# STM32N647 register map
File version: 1.0
CPU: CM55 r0p1, little endian, no MPU, FPU, vendor SysTick, 8 interrupt priority bits
Registers are 32-bit, read-write, reset 0x0 unless marked. A register's access mark holds for its fields unless they carry their own. Offsets are from the block's base; [hi:lo] are bit positions; {n}, {i} and the like mark numbered series; 'fields as' and 'values as' point back to an identical list.

## RCC (part 1 of 2) — Reset and clock control
Base 0x46028000
Same registers: RCC_S 0x56028000
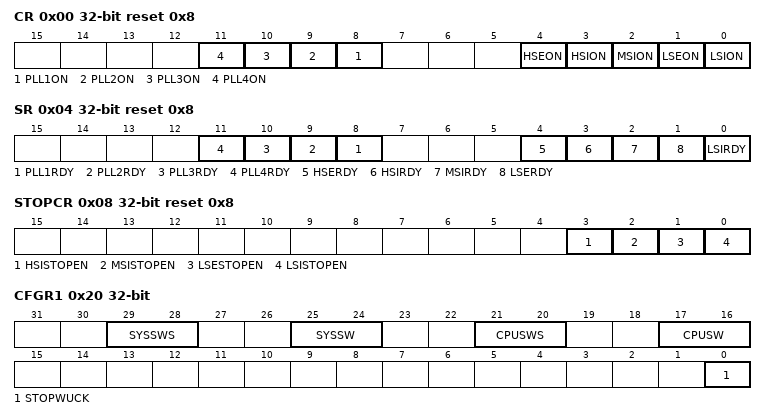
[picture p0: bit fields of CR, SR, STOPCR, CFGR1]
0x00 CR reset 0x8 — RCC control register
  [n+7] PLL{n}ON (n=1..4) — PLL{n} enable in Run/Sleep mode.
  [4] HSEON — HSE oscillator enable in Run/Sleep mode.
  [3] HSION — HSI oscillator enable in Run/Sleep mode.
  [2] MSION — MSI oscillator enable in Run/Sleep mode.
  [1] LSEON — LSE oscillator enable in Run/Sleep mode.
  [0] LSION — LSI oscillator enable in Run/Sleep mode.
0x04 SR ro reset 0x8 — RCC status register
  [n+7] PLL{n}RDY (n=1..4) — PLL{n} clock ready flag
  [4] HSERDY — HSE clock ready flag
  [3] HSIRDY — HSI clock ready flag
  [2] MSIRDY — MSI clock ready flag
  [1] LSERDY — LSE clock ready flag
  [0] LSIRDY — LSI clock ready flag
0x08 STOPCR reset 0x8 — RCC Stop mode control register
  [3] HSISTOPEN — HSI oscillator enable in Stop mode.
  [2] MSISTOPEN — MSI oscillator enable in Stop mode.
  [1] LSESTOPEN — LSE oscillator enable in Stop mode.
  [0] LSISTOPEN — LSI oscillator enable in Stop mode.
0x20 CFGR1 access per field — RCC configuration register 1
  [29:28] SYSSWS ro — System clock switch status
  [25:24] SYSSW rw — System clock switch selection
  [21:20] CPUSWS ro — CPU clock switch status
  [17:16] CPUSW rw — CPU clock switch selection
  [0] STOPWUCK rw — System clock selection after a wake up from system Stop.
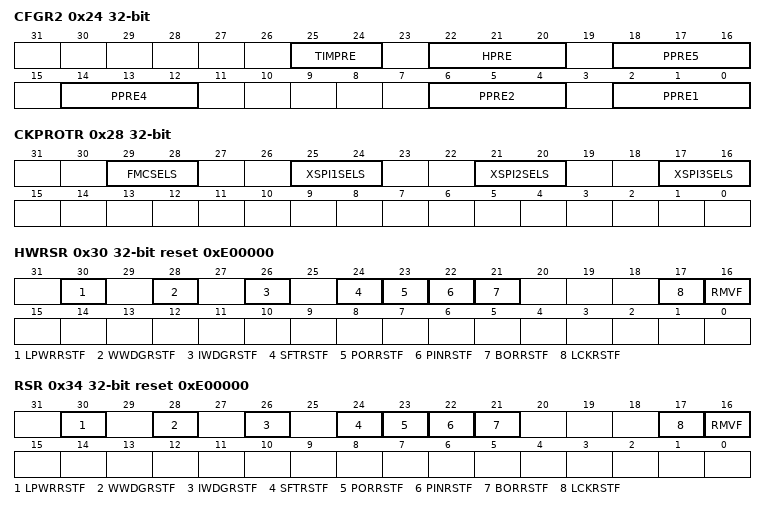
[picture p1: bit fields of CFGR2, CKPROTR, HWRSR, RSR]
0x24 CFGR2 — RCC configuration register 2
  [25:24] TIMPRE — Timers clocks prescaler selection
  [22:20] HPRE — AHB clock prescaler
  [18:16] PPRE5 — CPU domain APB5 prescaler
  [14:12] PPRE4 — CPU domain APB4 prescaler
  [6:4] PPRE2 — CPU domain APB2 prescaler
  [2:0] PPRE1 — CPU domain APB1 prescaler
0x28 CKPROTR ro — RCC clock protection register
  [29:28] FMCSELS — FMC clock selection current status
  [25:24] XSPI1SELS — XSPI1 clock selection current status
  [21:20] XSPI2SELS — XSPI2 clock selection current status
  [17:16] XSPI3SELS — XSPI3 clock selection current status
0x2C BDCR — RCC backup domain protection register
  [31] VSWRST — VSW domain software reset.
0x30 HWRSR access per field reset 0xE00000 — RCC reset status register for hardware
  [30] LPWRRSTF ro — Illegal Stop or Standby flag.
  [28] WWDGRSTF ro — Window watchdog reset flag
  [26] IWDGRSTF ro — Independent Watchdog reset flag.
  [24] SFTRSTF ro — Software system reset flag (1)
  [23] PORRSTF ro — POR/PDR flag.
  [22] PINRSTF ro — Pin reset flag (NRST)
  [21] BORRSTF ro — BOR flag
  [17] LCKRSTF ro — CPU lockup reset flag.
  [16] RMVF wo — Remove reset flag
0x34 RSR access per field reset 0xE00000 — RCC reset register
  [30] LPWRRSTF ro — Illegal Stop or Standby flag.
  [28] WWDGRSTF ro — Window Watchdog reset flag
  [26] IWDGRSTF ro — Independent Watchdog reset flag.
  [24] SFTRSTF ro — Software System reset flag (1)
  [23] PORRSTF ro — POR/PDR flag.
  [22] PINRSTF ro — Pin reset flag (NRST)
  [21] BORRSTF ro — BOR flag
  [17] LCKRSTF ro — CPU lockup reset flag.
  [16] RMVF wo — Remove reset flag
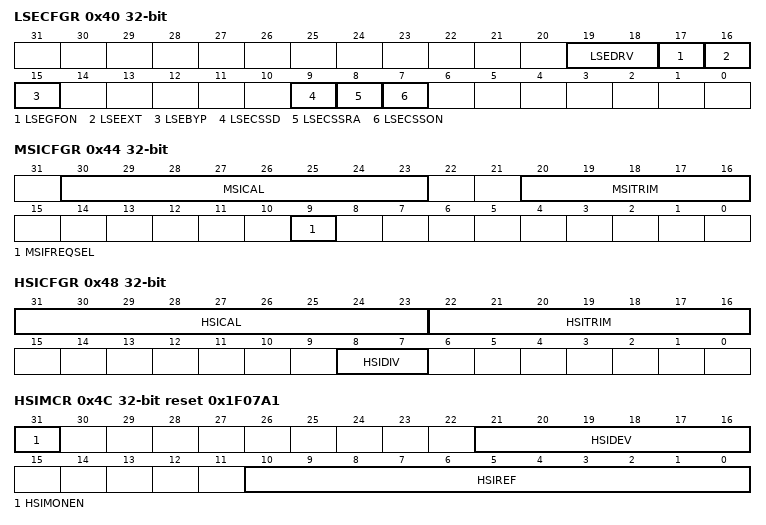
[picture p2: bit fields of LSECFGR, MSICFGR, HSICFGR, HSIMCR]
0x40 LSECFGR access per field — RCC LSE configuration register
  [19:18] LSEDRV rw — LSE oscillator driving capability
  [17] LSEGFON rw — LSE clock glitch filter enable
  [16] LSEEXT rw — LSE clock type in Bypass mode
  [15] LSEBYP rw — LSE clock bypass
  [9] LSECSSD ro — LSE clock security system (CSS) failure detection
  [8] LSECSSRA rw — LSE clock security system (CSS) re-arm function
  [7] LSECSSON wo — LSE clock security system (CSS) enable
0x44 MSICFGR access per field — RCC MSI configuration register
  [30:23] MSICAL ro — MSI clock calibration
  [20:16] MSITRIM rw — MSI clock trimming
  [9] MSIFREQSEL rw — MSI oscillator frequency select
0x48 HSICFGR access per field — RCC HSI configuration register
  [31:23] HSICAL ro — HSI clock calibration
  [22:16] HSITRIM rw — HSI clock trimming
  [8:7] HSIDIV rw — HSI clock divider
0x4C HSIMCR reset 0x1F07A1 — RCC HSI monitor control register
  [31] HSIMONEN — HSI clock period monitor enable
  [21:16] HSIDEV — HSI clock count deviation value
  [10:0] HSIREF — HSI clock cycle counter reference value.
0x50 HSIMSR ro — RCC HSI monitor status register
  [10:0] HSIVAL — HSI clock cycle counter measured value.
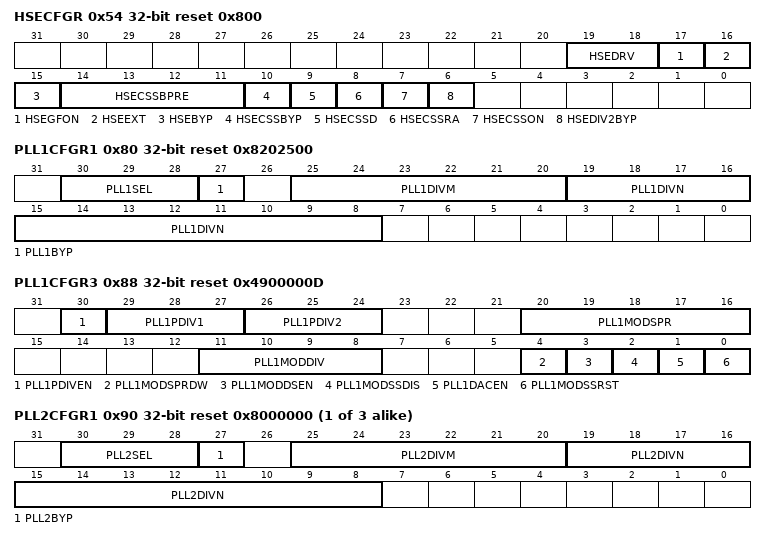
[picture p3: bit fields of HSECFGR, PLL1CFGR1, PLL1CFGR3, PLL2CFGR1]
0x54 HSECFGR access per field reset 0x800 — RCC HSE configuration register
  [19:18] HSEDRV rw — HSE oscillator driving capability
  [17] HSEGFON rw — HSE clock glitch filter enable
  [16] HSEEXT rw — HSE clock type in Bypass mode
  [15] HSEBYP rw — HSE clock bypass
  [14:11] HSECSSBPRE rw — HSE clock security system (CSS) bypass divider
  [10] HSECSSBYP rw — HSE clock security system (CSS) bypass enable
  [9] HSECSSD ro — HSE clock security system (CSS) failure detection
  [8] HSECSSRA rw — HSE clock security system (CSS) re-arm function
  [7] HSECSSON rw — HSE clock security system (CSS) enable
  [6] HSEDIV2BYP rw — HSE div2 oscillator clock in Bypass mode
0x80 PLL1CFGR1 reset 0x8202500 — RCC PLL1 configuration register 1
  [30:28] PLL1SEL — PLL1 source selection of the reference clock
  [27] PLL1BYP — PLL1 bypass
  [25:20] PLL1DIVM — PLL1 reference input clock divide frequency ratio
  [19:8] PLL1DIVN — PLL1 Integer part for the VCO multiplication factor
0x84 PLL1CFGR2 reset 0x800000 — RCC PLL1 configuration register 2
  [23:0] PLL1DIVNFRAC — PLL1 Fractional part of the VCO multiplication factor
0x88 PLL1CFGR3 reset 0x4900000D — RCC PLL1 configuration register 3
  [30] PLL1PDIVEN — PLL1 post divider POSTDIV1, POSTDIV2, and PLL clock output enable
  [29:27] PLL1PDIV1 — PLL1 VCO frequency divider level 1
  [26:24] PLL1PDIV2 — PLL1 VCO frequency divider level 2
  [20:16] PLL1MODSPR — PLL1 Modulation Spread depth adjustment
  [11:8] PLL1MODDIV — PLL1 Modulation Division frequency adjustment
  [4] PLL1MODSPRDW — PLL1 Modulation Spread-Spectrum Down
  [3] PLL1MODDSEN — PLL1 Modulation Spread-Spectrum (and Fractional Divide) enable
  [2] PLL1MODSSDIS — PLL1 Modulation Spread-Spectrum Disable
  [1] PLL1DACEN — PLL1 noise canceling DAC enable in fractional mode.
  [0] PLL1MODSSRST — PLL1 Modulation Spread Spectrum reset
{0x70+0x10*i} PLL{i}CFGR1 reset 0x8000000 (i=2..4) — RCC PLL{i} configuration register 1
  [30:28] PLL{i}SEL — PLL{i} source selection of the reference clock
  [27] PLL{i}BYP — PLL{i} bypass
  [25:20] PLL{i}DIVM — PLL{i} reference input clock divide frequency ratio
  [19:8] PLL{i}DIVN — PLL{i} Integer part for the VCO multiplication factor
{0x74+0x10*i} PLL{i}CFGR2 (i=2..4) — RCC PLL{i} configuration register 2
  [23:0] PLL{i}DIVNFRAC — PLL{i} Fractional part of the VCO multiplication factor
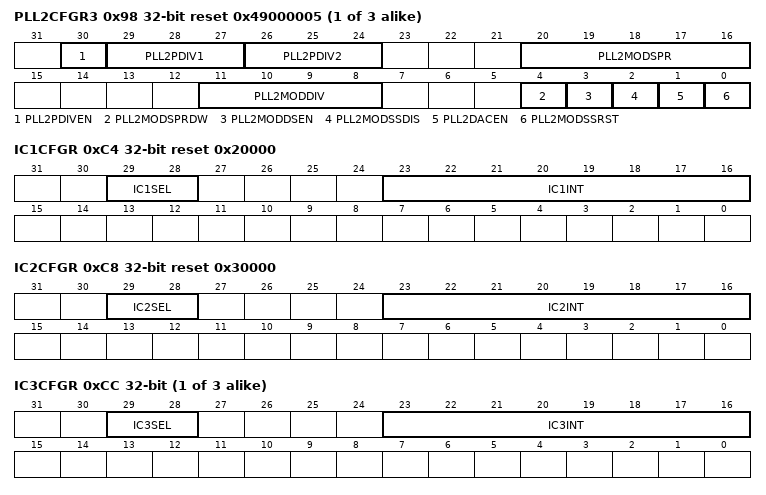
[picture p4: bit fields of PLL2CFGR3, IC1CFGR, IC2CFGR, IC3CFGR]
{0x78+0x10*i} PLL{i}CFGR3 reset 0x49000005 (i=2..4) — RCC PLL{i} configuration register 3
  [30] PLL{i}PDIVEN — PLL{i} post divider POSTDIV1, POSTDIV2, and PLL clock output enable
  [29:27] PLL{i}PDIV1 — PLL{i} VCO frequency divider level 1
  [26:24] PLL{i}PDIV2 — PLL{i} VCO frequency divider level 2
  [20:16] PLL{i}MODSPR — PLL{i} Modulation Spread depth adjustment
  [11:8] PLL{i}MODDIV — PLL{i} Modulation Division frequency adjustment
  [4] PLL{i}MODSPRDW — PLL{i} Modulation Down Spread
  [3] PLL{i}MODDSEN — PLL{i} Modulation Spread-Spectrum (and Fractional Divide) enable
  [2] PLL{i}MODSSDIS — PLL{i} Modulation Spread-Spectrum Disable
  [1] PLL{i}DACEN — PLL{i} noise canceling DAC enable in fractional mode.
  [0] PLL{i}MODSSRST — PLL{i} Modulation Spread Spectrum reset
0xC4 IC1CFGR reset 0x20000 — RCC IC1 configuration register
  [29:28] IC1SEL — Divider IC1 Source Selection
  [23:16] IC1INT — Divider IC1 integer division factor
0xC8 IC2CFGR reset 0x30000 — RCC IC2 configuration register
  [29:28] IC2SEL — Divider IC2 Source Selection
  [23:16] IC2INT — Divider IC2 integer division factor
{0xC0+4i} IC{i}CFGR (i=3..5) — RCC IC{i} configuration register
  [29:28] IC{i}SEL — Divider IC{i} Source Selection
  [23:16] IC{i}INT — Divider IC{i} integer division factor
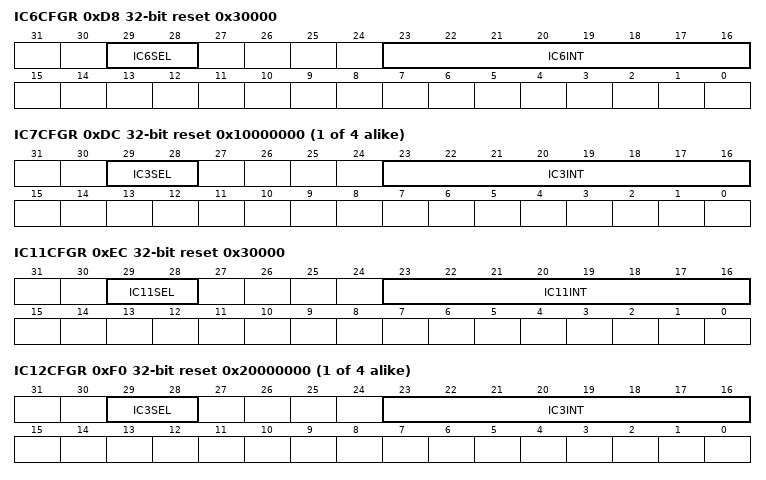
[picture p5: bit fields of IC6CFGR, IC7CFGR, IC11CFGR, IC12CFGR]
0xD8 IC6CFGR reset 0x30000 — RCC IC6 configuration register
  [29:28] IC6SEL — Divider IC6 Source Selection
  [23:16] IC6INT — Divider IC6 integer division factor
{0xC0+4i} IC{i}CFGR reset 0x10000000 (i=7..10) — RCC IC{i} configuration register
  fields as IC3CFGR
0xEC IC11CFGR reset 0x30000 — RCC IC11 configuration register
  [29:28] IC11SEL — Divider IC11 Source Selection
  [23:16] IC11INT — Divider IC11 integer division factor
{0xC0+4i} IC{i}CFGR reset 0x20000000 (i=12..15) — RCC IC{i} configuration register
  fields as IC3CFGR
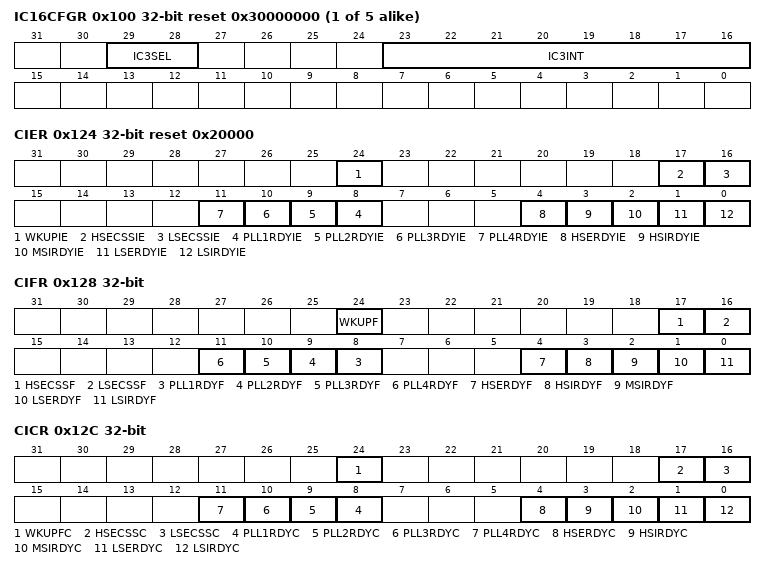
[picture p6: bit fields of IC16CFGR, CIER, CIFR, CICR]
{0xC0+4i} IC{i}CFGR reset 0x30000000 (i=16..20) — RCC IC{i} configuration register
  fields as IC3CFGR
0x124 CIER reset 0x20000 — RCC clock-source interrupt enable register
  [24] WKUPIE — CPU wakeup from Stop interrupt enable
  [17] HSECSSIE — HSE clock security system (CSS) interrupt enable
  [16] LSECSSIE — LSE clock security system (CSS) interrupt enable
  [n+7] PLL{n}RDYIE (n=1..4) — PLL{n} ready interrupt enable
  [4] HSERDYIE — HSE ready interrupt enable
  [3] HSIRDYIE — HSI ready interrupt enable
  [2] MSIRDYIE — MSI ready interrupt enable
  [1] LSERDYIE — LSE ready interrupt enable
  [0] LSIRDYIE — LSI ready interrupt enable
0x128 CIFR ro — RCC clock-source interrupt flag register
  [24] WKUPF — CPU wakeup from Stop interrupt flag
  [17] HSECSSF — HSE ready interrupt flag
  [16] LSECSSF — LSE ready interrupt flag
  [n+7] PLL{n}RDYF (n=1..4) — PLL{n} ready interrupt flag
  [4] HSERDYF — HSE ready interrupt flag
  [3] HSIRDYF — HSI ready interrupt flag
  [2] MSIRDYF — MSI ready interrupt flag
  [1] LSERDYF — LSE ready interrupt flag
  [0] LSIRDYF — LSI ready interrupt flag
0x12C CICR wo — RCC clock-source interrupt Clear register
  [24] WKUPFC — CPU Wakeup ready interrupt clear
  [17] HSECSSC — HSE ready interrupt clear
  [16] LSECSSC — LSE ready interrupt clear
  [n+7] PLL{n}RDYC (n=1..4) — PLL{n} ready interrupt clear
  [4] HSERDYC — HSE ready interrupt clear
  [3] HSIRDYC — HSI ready interrupt clear
  [2] MSIRDYC — MSI ready interrupt clear
  [1] LSERDYC — LSE ready interrupt clear
  [0] LSIRDYC — LSI ready interrupt clear
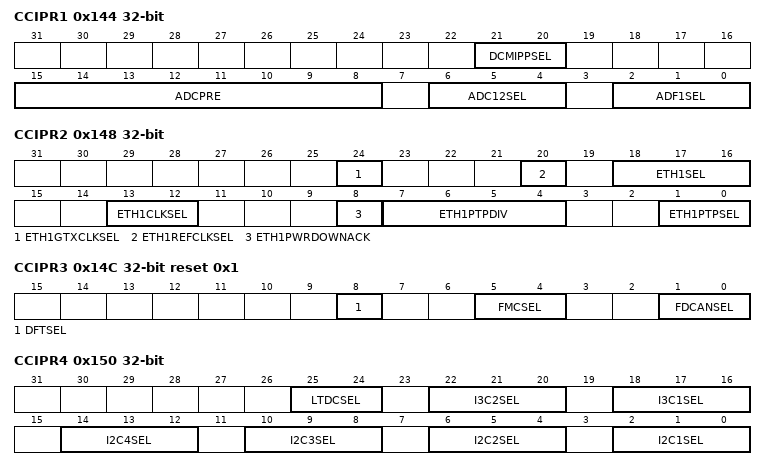
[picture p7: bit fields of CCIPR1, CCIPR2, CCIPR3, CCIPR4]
0x144 CCIPR1 — RCC clock configuration for independent peripheral register1
  [21:20] DCMIPPSEL — Source selection for the DCMIPP kernel clock
  [15:8] ADCPRE — ADC12 Prog clock divider selection (for clock ck_icn_p_adf1)
  [6:4] ADC12SEL — Source selection for the ADC12 kernel clock
  [2:0] ADF1SEL — Source selection for the ADF1 kernel clock
0x148 CCIPR2 access per field — RCC clock configuration for independent peripheral register 2
  [24] ETH1GTXCLKSEL rw — Set and reset by software.
  [20] ETH1REFCLKSEL rw — Set and reset by software
  [18:16] ETH1SEL rw — Set and reset by software
  [13:12] ETH1CLKSEL rw — Source selection for the ETH1 kernel clock
  [8] ETH1PWRDOWNACK ro — Set and reset by software.
  [7:4] ETH1PTPDIV rw — ETH1 Kernel clock divider selection (for clock ck_ker_eth1ptp)
  [1:0] ETH1PTPSEL rw — Source selection for the ETH1 kernel clock
0x14C CCIPR3 reset 0x1 — RCC clock configuration for independent peripheral register3
  [8] DFTSEL — Source selection for the DFT kernel clock
  [5:4] FMCSEL — Source selection for the FMC kernel clock
  [1:0] FDCANSEL — Source selection for the FDCAN kernel clock
0x150 CCIPR4 — RCC clock configuration for independent peripheral register4
  [25:24] LTDCSEL — Source selection for the LTDC kernel clock
  [22:20] I3C2SEL — Source selection for the I3C2 kernel clock
  [18:16] I3C1SEL — Source selection for the I3C1 kernel clock
  [4n-2:4n-4] I2C{n}SEL (n=1..4) — Source selection for the I2C{n} kernel clock
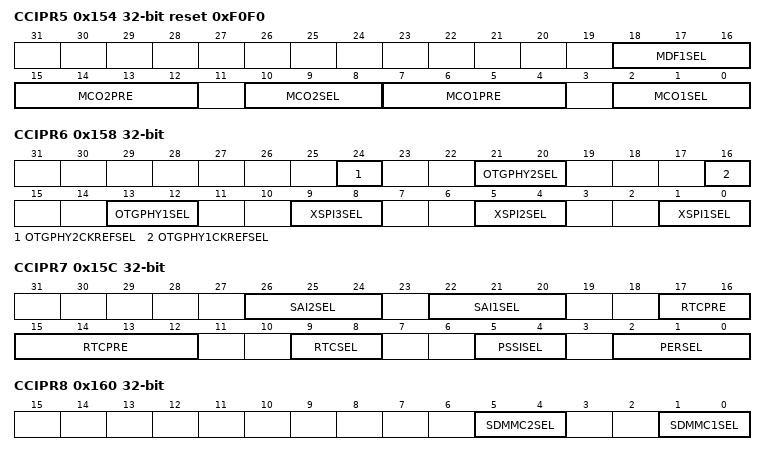
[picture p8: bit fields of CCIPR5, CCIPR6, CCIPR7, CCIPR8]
0x154 CCIPR5 reset 0xF0F0 — RCC lock configuration for independent peripheral register5
  [18:16] MDF1SEL — Source selection for the MDF1 kernel clock
  [15:12] MCO2PRE — MCO2 Prog clock divider selection (for clock ck_icn_p_mce4)
  [10:8] MCO2SEL — Source selection for the MCO2 kernel clock
  [7:4] MCO1PRE — MCO1 Prog clock divider selection (for clock ck_icn_p_mce3)
  [2:0] MCO1SEL — Source selection for the MCO1 kernel clock
0x158 CCIPR6 — RCC clock configuration for independent peripheral register6
  [24] OTGPHY2CKREFSEL — Set and reset by software
  [21:20] OTGPHY2SEL — Source selection for the OTGPHY2 kernel clock
  [16] OTGPHY1CKREFSEL — Set and reset by software
  [13:12] OTGPHY1SEL — Source selection for the OTGPHY1 kernel clock
  [9:8] XSPI3SEL — Source selection for the XSPI3 kernel clock
  [5:4] XSPI2SEL — Source selection for the XSPI2 kernel clock
  [1:0] XSPI1SEL — Source selection for the XSPI1 kernel clock
0x15C CCIPR7 — RCC clock configuration for independent peripheral register7
  [26:24] SAI2SEL — Source selection for the SAI2 kernel clock
  [22:20] SAI1SEL — Source selection for the SAI1 kernel clock
  [17:12] RTCPRE — RTC Prog clock divider selection (for clock ck_icn_p_risaf)
  [9:8] RTCSEL — Source selection for the RTC kernel clock
  [5:4] PSSISEL — Source selection for the PSSI kernel clock
  [2:0] PERSEL — Source selection for the PER kernel clock
0x160 CCIPR8 — RCC clock configuration for independent peripheral register8
  [5:4] SDMMC2SEL — Source selection for the SDMMC2 kernel clock
  [1:0] SDMMC1SEL — Source selection for the SDMMC1 kernel clock
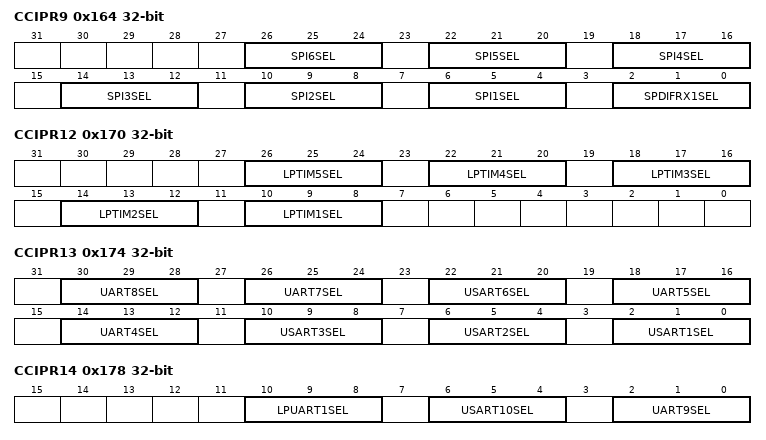
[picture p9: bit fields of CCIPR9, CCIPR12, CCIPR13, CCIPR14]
0x164 CCIPR9 — RCC clock configuration for independent peripheral register9
  [4n+2:4n] SPI{n}SEL (n=1..6) — Source selection for the SPI{n} kernel clock
  [2:0] SPDIFRX1SEL — Source selection for the SPDIFRX1 kernel clock
0x170 CCIPR12 — RCC clock configuration for independent peripheral register12
  [4n+6:4n+4] LPTIM{n}SEL (n=1..5) — Source selection for the LPTIM{n} kernel clock
0x174 CCIPR13 — RCC clock configuration for independent peripheral register13
  [30:28] UART8SEL — Source selection for the UART8 kernel clock
  [26:24] UART7SEL — Source selection for the UART7 kernel clock
  [22:20] USART6SEL — Source selection for the USART6 kernel clock
  [18:16] UART5SEL — Source selection for the UART5 kernel clock
  [14:12] UART4SEL — Source selection for the UART4 kernel clock
  [10:8] USART3SEL — Source selection for the USART3 kernel clock
  [6:4] USART2SEL — Source selection for the USART2 kernel clock
  [2:0] USART1SEL — Source selection for the USART1 kernel clock
0x178 CCIPR14 — RCC clock configuration for independent peripheral register14
  [10:8] LPUART1SEL — Source selection for the LPUART1 kernel clock
  [6:4] USART10SEL — Source selection for the USART10 kernel clock
  [2:0] UART9SEL — Source selection for the UART9 kernel clock
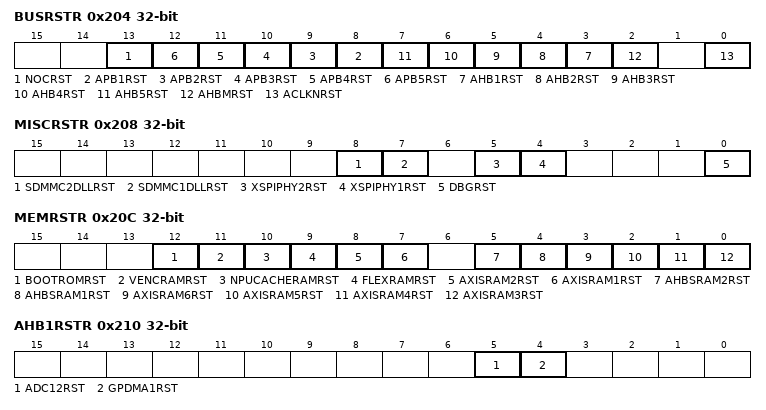
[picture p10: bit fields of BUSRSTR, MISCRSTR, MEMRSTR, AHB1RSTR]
0x204 BUSRSTR — RCC SoC buses reset register
  [13] NOCRST — NOC reset
  [n+7] APB{n}RST (n=1..5) — APB{n} reset
  [n+2] AHB{n}RST (n=1..5) — AHB{n} reset
  [2] AHBMRST — AHBM reset
  [0] ACLKNRST — ACLKN reset
0x208 MISCRSTR — RCC miscellaneous configurations reset register
  [8] SDMMC2DLLRST — SDMMC2DLL reset
  [7] SDMMC1DLLRST — SDMMC1DLL reset
  [5] XSPIPHY2RST — XSPIPHY2 reset
  [4] XSPIPHY1RST — XSPIPHY1 reset
  [0] DBGRST — DBG reset
0x20C MEMRSTR — RCC memories reset register
  [12] BOOTROMRST — BOOTROM reset
  [11] VENCRAMRST — VENCRAM reset
  [10] NPUCACHERAMRST — NPUCACHERAM reset
  [9] FLEXRAMRST — FLEXRAM reset
  [8] AXISRAM2RST — AXISRAM2 reset
  [7] AXISRAM1RST — AXISRAM1 reset
  [5] AHBSRAM2RST — AHBSRAM2 reset
  [4] AHBSRAM1RST — AHBSRAM1 reset
  [3] AXISRAM6RST — AXISRAM6 reset
  [2] AXISRAM5RST — AXISRAM5 reset
  [1] AXISRAM4RST — AXISRAM4reset
  [0] AXISRAM3RST — AXISRAM3 reset
0x210 AHB1RSTR — RCC AHB1 Reset register
  [5] ADC12RST — ADC12 reset
  [4] GPDMA1RST — GPDMA1 reset
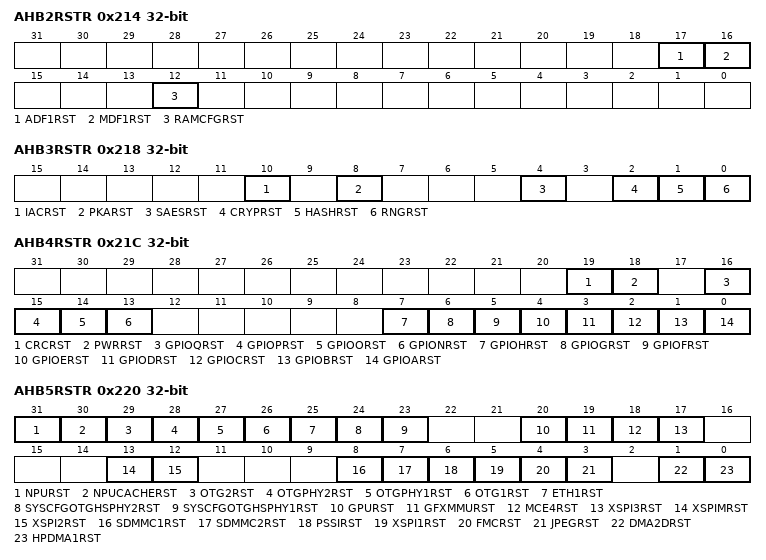
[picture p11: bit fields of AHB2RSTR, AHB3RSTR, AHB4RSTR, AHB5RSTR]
0x214 AHB2RSTR — RCC AHB2 reset register
  [17] ADF1RST — ADF1 reset
  [16] MDF1RST — MDF1 reset
  [12] RAMCFGRST — RAMCFG reset
0x218 AHB3RSTR — RCC AHB3 reset register
  [10] IACRST — IAC reset
  [8] PKARST — PKA reset
  [4] SAESRST — SAES reset
  [2] CRYPRST — CRYP reset
  [1] HASHRST — HASH reset
  [0] RNGRST — RNG reset
0x21C AHB4RSTR — RCC AHB4 reset register
  [19] CRCRST — CRC reset
  [18] PWRRST — PWR reset
  [16] GPIOQRST — GPIOQ reset
  [15] GPIOPRST — GPIOP reset
  [14] GPIOORST — GPIOO reset
  [13] GPIONRST — GPION reset
  [7] GPIOHRST — GPIOH reset
  [6] GPIOGRST — GPIOG reset
  [5] GPIOFRST — GPIOF reset
  [4] GPIOERST — GPIOE reset
  [3] GPIODRST — GPIOD reset
  [2] GPIOCRST — GPIOC reset
  [1] GPIOBRST — GPIOB reset
  [0] GPIOARST — GPIOA reset
0x220 AHB5RSTR — RCC AHB5 reset register
  [31] NPURST — NPU reset
  [30] NPUCACHERST — NPUCACHE reset
  [29] OTG2RST — OTG2 reset
  [28] OTGPHY2RST — OTGPHY2 reset
  [27] OTGPHY1RST — OTGPHY1 reset
  [26] OTG1RST — OTG1 reset
  [25] ETH1RST — ETH1 reset
  [24] SYSCFGOTGHSPHY2RST — SYSCFGOTGHSPHY2 reset
  [23] SYSCFGOTGHSPHY1RST — SYSCFGOTGHSPHY1 reset
  [20] GPURST — GPU reset
  [19] GFXMMURST — GFXMMU reset
  [18] MCE4RST — MCE4 reset
  [17] XSPI3RST — XSPI3 reset
  [13] XSPIMRST — XSPIM reset
  [12] XSPI2RST — XSPI2 reset
  [8] SDMMC1RST — SDMMC1 reset
  [7] SDMMC2RST — SDMMC2 reset
  [6] PSSIRST — PSSI reset
  [5] XSPI1RST — XSPI1 reset
  [4] FMCRST — FMC reset
  [3] JPEGRST — JPEG reset
  [1] DMA2DRST — DMA2D reset
  [0] HPDMA1RST — HPDMA1 reset
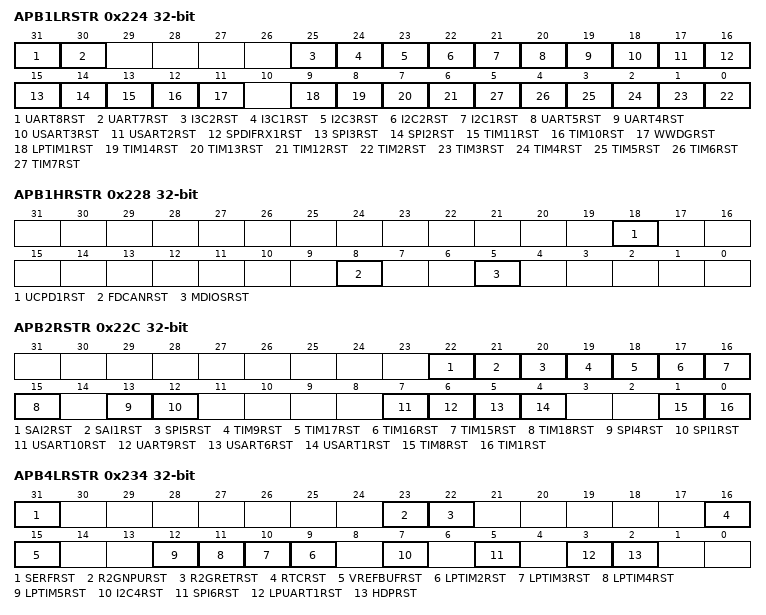
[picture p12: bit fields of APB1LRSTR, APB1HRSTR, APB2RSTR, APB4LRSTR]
0x224 APB1LRSTR — RCC APB1L reset register
  [31] UART8RST — UART8 reset
  [30] UART7RST — UART7 reset
  [25] I3C2RST — I3C2 reset
  [24] I3C1RST — I3C1 reset
  [23] I2C3RST — I2C3 reset
  [22] I2C2RST — I2C2 reset
  [21] I2C1RST — I2C1 reset
  [20] UART5RST — UART5 reset
  [19] UART4RST — UART4 reset
  [18] USART3RST — USART3 reset
  [17] USART2RST — USART2 reset
  [16] SPDIFRX1RST — SPDIFRX1 reset
  [15] SPI3RST — SPI3 reset
  [14] SPI2RST — SPI2 reset
  [13] TIM11RST — TIM11 reset
  [12] TIM10RST — TIM10 reset
  [11] WWDGRST — WWDG reset
  [9] LPTIM1RST — LPTIM1 reset
  [8] TIM14RST — TIM14 reset
  [7] TIM13RST — TIM13 reset
  [6] TIM12RST — TIM12 reset
  [n-2] TIM{n}RST (n=2..7) — TIM{n} reset
0x228 APB1HRSTR — RCC APB1H reset register
  [18] UCPD1RST — UCPD1 reset
  [8] FDCANRST — FDCAN reset
  [5] MDIOSRST — MDIOS reset
0x22C APB2RSTR — RCC APB2 reset register
  [22] SAI2RST — SAI2 reset
  [21] SAI1RST — SAI1 reset
  [20] SPI5RST — SPI5 reset
  [19] TIM9RST — TIM9 reset
  [18] TIM17RST — TIM17 reset
  [17] TIM16RST — TIM16 reset
  [16] TIM15RST — TIM15 reset
  [15] TIM18RST — TIM18 reset
  [13] SPI4RST — SPI4 reset
  [12] SPI1RST — SPI1 reset
  [7] USART10RST — USART10 reset
  [6] UART9RST — UART9 reset
  [5] USART6RST — USART6 reset
  [4] USART1RST — USART1 reset
  [1] TIM8RST — TIM8 reset
  [0] TIM1RST — TIM1 reset
0x234 APB4LRSTR — RCC APB4L reset register
  [31] SERFRST — SERF reset
  [23] R2GNPURST — R2GNPU reset
  [22] R2GRETRST — R2GRET reset
  [16] RTCRST — RTC reset
  [15] VREFBUFRST — VREFBUF reset
  [n+7] LPTIM{n}RST (n=2..5) — LPTIM{n} reset
  [7] I2C4RST — I2C4 reset
  [5] SPI6RST — SPI6 reset
  [3] LPUART1RST — LPUART1 reset
  [2] HDPRST — HDP reset
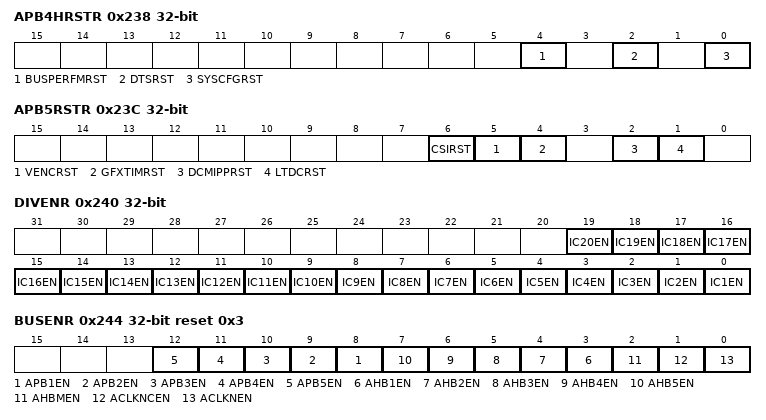
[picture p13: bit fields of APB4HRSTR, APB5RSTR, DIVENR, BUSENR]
0x238 APB4HRSTR — RCC APB4H reset register
  [4] BUSPERFMRST — BUSPERFM reset
  [2] DTSRST — DTS reset
  [0] SYSCFGRST — SYSCFG reset
0x23C APB5RSTR — RCC APB5 reset register
  [6] CSIRST — CSI reset
  [5] VENCRST — VENC reset
  [4] GFXTIMRST — GFXTIM reset
  [2] DCMIPPRST — DCMIPP reset
  [1] LTDCRST — LTDC reset
0x240 DIVENR — RCC IC dividers enable register
  [n-1] IC{n}EN (n=1..20) — IC{n} enable
0x244 BUSENR reset 0x3 — RCC SoC buses enable register
  [n+7] APB{n}EN (n=1..5) — APB{n} enable
  [n+2] AHB{n}EN (n=1..5) — AHB{n} enable
  [2] AHBMEN — AHBM enable
  [1] ACLKNCEN — ACLKNC enable
  [0] ACLKNEN — ACLKN enable
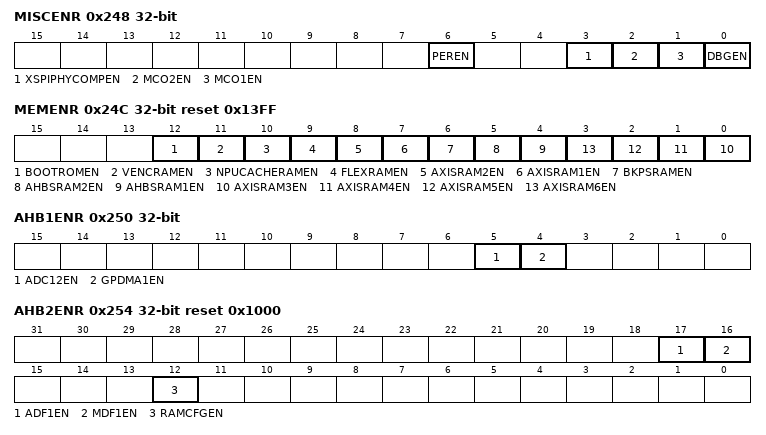
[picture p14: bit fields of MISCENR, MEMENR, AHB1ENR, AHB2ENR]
0x248 MISCENR — RCC miscellaneous configuration enable register
  [6] PEREN — PER enable
  [3] XSPIPHYCOMPEN — XSPIPHYCOMP enable
  [2] MCO2EN — MCO2 enable
  [1] MCO1EN — MCO1 enable
  [0] DBGEN — DBG enable
0x24C MEMENR reset 0x13FF — RCC memory enable register
  [12] BOOTROMEN — BOOTROM enable
  [11] VENCRAMEN — VENCRAM enable
  [10] NPUCACHERAMEN — NPUCACHERAM enable
  [9] FLEXRAMEN — FLEXRAM enable
  [8] AXISRAM2EN — AXISRAM2 enable
  [7] AXISRAM1EN — AXISRAM1 enable
  [6] BKPSRAMEN — BKPSRAM enable
  [5] AHBSRAM2EN — AHBSRAM2 enable
  [4] AHBSRAM1EN — AHBSRAM1 enable
  [n-3] AXISRAM{n}EN (n=3..6) — AXISRAM{n} enable
0x250 AHB1ENR — RCC AHB1 enable register
  [5] ADC12EN — ADC12 enable
  [4] GPDMA1EN — GPDMA1 enable
0x254 AHB2ENR reset 0x1000 — RCC AHB2 enable register
  [17] ADF1EN — ADF enable
  [16] MDF1EN — MDF1 enable
  [12] RAMCFGEN — RAMCFG enable
0x258 AHB3ENR reset 0x4600 — RCC AHB3 enable register
  [14] RISAFEN — RISAF enable
  [10] IACEN — IAC enable
  [9] RIFSCEN — RIFSC enable
  [8] PKAEN — PKA enable
  [4] SAESEN — SAES enable
  [2] CRYPEN — CRYP enable
  [1] HASHEN — HASH enable
  [0] RNGEN — RNG enable
0x25C AHB4ENR reset 0x40000 — RCC AHB4 enable register
  [19] CRCEN — CRC enable
  [18] PWREN — PWR enable
  [16] GPIOQEN — GPIOQ enable
  [15] GPIOPEN — GPIOP enable
  [14] GPIOOEN — GPIOO enable
  [13] GPIONEN — GPION enable
  [7] GPIOHEN — GPIOH enable
  [6] GPIOGEN — GPIOG enable
  [5] GPIOFEN — GPIOF enable
  [4] GPIOEEN — GPIOE enable
  [3] GPIODEN — GPIOD enable
  [2] GPIOCEN — GPIOC enable
  [1] GPIOBEN — GPIOB enable
  [0] GPIOAEN — GPIOA enable
0x260 AHB5ENR — RCC AHB5 enable register
  [31] NPUEN — NPU enable
  [30] NPUCACHEEN — NPUCACHE enable
  [29] OTG2EN — OTG2 enable
  [28] OTGPHY2EN — OTGPHY2 enable
  [27] OTGPHY1EN — OTGPHY1 enable
  [26] OTG1EN — OTG1 enable
  [25] ETH1EN — ETH1 enable
  [24] ETH1RXEN — ETH1RX enable
  [23] ETH1TXEN — ETH1TX enable
  [22] ETH1MACEN — ETH1MAC enable
  [20] GPUEN — GPU enable
  [19] GFXMMUEN — GFXMMU enable
  [18] MCE4EN — MCE4 enable
  [17] XSPI3EN — XSPI3 enable
  [16] MCE3EN — MCE3 enable
  [15] MCE2EN — MCE2 enable
  [14] MCE1EN — MCE1 enable
  [13] XSPIMEN — XSPIM enable
  [12] XSPI2EN — XSPI2 enable
  [8] SDMMC1EN — SDMMC1 enable
  [7] SDMMC2EN — SDMMC2 enable
  [6] PSSIEN — PSSI enable
  [5] XSPI1EN — XSPI1 enable
  [4] FMCEN — FMC enable
  [3] JPEGEN — JPEG enable
  [1] DMA2DEN — DMA2D enable
  [0] HPDMA1EN — HPDMA1 enable
0x264 APB1LENR — RCC APB1L enable register
  [31] UART8EN — UART8 enable
  [30] UART7EN — UART7 enable
  [25] I3C2EN — I3C2 enable
  [24] I3C1EN — I3C1 enable
  [23] I2C3EN — I2C3 enable
  [22] I2C2EN — I2C2 enable
  [21] I2C1EN — I2C1 enable
  [20] UART5EN — UART5 enable
  [19] UART4EN — UART4 enable
  [18] USART3EN — USART3 enable
  [17] USART2EN — USART2 enable
  [16] SPDIFRX1EN — SPDIFRX1 enable
  [15] SPI3EN — SPI3 enable
  [14] SPI2EN — SPI2 enable
  [13] TIM11EN — TIM11 enable
  [12] TIM10EN — TIM10 enable
  [11] WWDGEN — WWDG enable
  [9] LPTIM1EN — LPTIM1 enable
  [8] TIM14EN — TIM14 enable
  [7] TIM13EN — TIM13 enable
  [6] TIM12EN — TIM12 enable
  [n-2] TIM{n}EN (n=2..7) — TIM{n} enable
0x268 APB1HENR — RCC APB1H enable register
  [18] UCPD1EN — UCPD1 enable
  [8] FDCANEN — FDCAN enable
  [5] MDIOSEN — MDIOS enable
0x26C APB2ENR — RCC APB2 enable register
  [22] SAI2EN — SAI2 enable
  [21] SAI1EN — SAI1 enable
  [20] SPI5EN — SPI5 enable
  [19] TIM9EN — TIM9 enable
  [18] TIM17EN — TIM17 enable
  [17] TIM16EN — TIM16 enable
  [16] TIM15EN — TIM15 enable
  [15] TIM18EN — TIM18 enable
  [13] SPI4EN — SPI4 enable
  [12] SPI1EN — SPI1 enable
  [7] USART10EN — USART10 enable
  [6] UART9EN — UART9 enable
  [5] USART6EN — USART6 enable
  [4] USART1EN — USART1 enable
  [1] TIM8EN — TIM8 enable
  [0] TIM1EN — TIM1 enable
0x270 APB3ENR — RCC APB3 enable register
  [2] DFTEN — DFT enable
0x274 APB4LENR — RCC APB4L enable register
  [31] SERFEN — SERF enable
  [23] R2GNPUEN — R2GNPU enable
  [22] R2GRETEN — R2GRET enable
  [17] RTCAPBEN — RTCAPB enable
  [16] RTCEN — RTC enable
  [15] VREFBUFEN — VREFBUF enable
  [n+7] LPTIM{n}EN (n=2..5) — LPTIM{n} enable
  [7] I2C4EN — I2C4 enable
  [5] SPI6EN — SPI6 enable
  [3] LPUART1EN — LPUART1 enable
  [2] HDPEN — HDP enable
0x278 APB4HENR reset 0x2 — RCC APB4H enable register
  [4] BUSPERFMEN — BUSPERFM enable
  [2] DTSEN — DTS enable
  [1] BSECEN — BSEC enable
  [0] SYSCFGEN — SYSCFG enable
0x27C APB5ENR — RCC APB5 enable register
  [6] CSIEN — CSI enable
  [5] VENCEN — VENC enable
  [4] GFXTIMEN — GFXTIM enable
  [2] DCMIPPEN — DCMIPP enable
  [1] LTDCEN — LTDC enable
0x280 DIVLPENR — RCC dividers Sleep enable register
  [n-1] IC{n}LPEN (n=1..20) — IC{n} sleep enable
0x284 BUSLPENR reset 0x3 — RCC SoC buses Sleep enable register
  [n+7] APB{n}LPEN (n=1..5) — APB{n} sleep enable
  [n+2] AHB{n}LPEN (n=1..5) — AHB{n} sleep enable
  [2] AHBMLPEN — AHBM sleep enable
  [1] ACLKNCLPEN — ACLKNC sleep enable
  [0] ACLKNLPEN — ACLKN sleep enable
0x288 MISCLPENR — RCC miscellaneous configurations Sleep enable register
  [6] PERLPEN — PER sleep enable
  [3] XSPIPHYCOMPLPEN — XSPIPHYCOMP sleep enable
  [0] DBGLPEN — DBG sleep enable
0x28C MEMLPENR — RCC memory Sleep enable register
  [12] BOOTROMLPEN — BOOTROM sleep enable
  [11] VENCRAMLPEN — VENCRAM sleep enable
  [10] NPUCACHERAMLPEN — NPUCACHERAM sleep enable
  [9] FLEXRAMLPEN — FLEXRAM sleep enable
  [8] AXISRAM2LPEN — AXISRAM2 sleep enable
  [7] AXISRAM1LPEN — AXISRAM1 sleep enable
  [6] BKPSRAMLPEN — BKPSRAM sleep enable
  [5] AHBSRAM2LPEN — AHBSRAM2 sleep enable
  [4] AHBSRAM1LPEN — AHBSRAM1 sleep enable
  [n-3] AXISRAM{n}LPEN (n=3..6) — AXISRAM{n} sleep enable
0x290 AHB1LPENR — RCC AHB1 Sleep enable register
  [5] ADC12LPEN — ADC12 sleep enable
  [4] GPDMA1LPEN — GPDMA1 sleep enable
0x294 AHB2LPENR — RCC AHB2 Sleep enable register
  [17] ADF1LPEN — ADF1 sleep enable
  [16] MDF1LPEN — MDF1 sleep enable
  [12] RAMCFGLPEN — RAMCFG sleep enable
0x298 AHB3LPENR reset 0x400 — RCC AHB3 Sleep enable register
  [14] RISAFLPEN — RISAF sleep enable
  [10] IACLPEN — IAC sleep enable
  [9] RIFSCLPEN — RIFSC sleep enable
  [8] PKALPEN — PKA sleep enable
  [4] SAESLPEN — SAES sleep enable
  [2] CRYPLPEN — CRYP sleep enable
  [1] HASHLPEN — HASH sleep enable
  [0] RNGLPEN — RNG sleep enable
0x29C AHB4LPENR reset 0x40000 — RCC AHB4 Sleep enable register
  [19] CRCLPEN — CRC sleep enable
  [18] PWRLPEN — PWR sleep enable
  [16] GPIOQLPEN — GPIOQ sleep enable
  [15] GPIOPLPEN — GPIOP sleep enable
  [14] GPIOOLPEN — GPIOO sleep enable
  [13] GPIONLPEN — GPION sleep enable
  [7] GPIOHLPEN — GPIOH sleep enable
  [6] GPIOGLPEN — GPIOG sleep enable
  [5] GPIOFLPEN — GPIOF sleep enable
  [4] GPIOELPEN — GPIOE sleep enable
  [3] GPIODLPEN — GPIOD sleep enable
  [2] GPIOCLPEN — GPIOC sleep enable
  [1] GPIOBLPEN — GPIOB sleep enable
  [0] GPIOALPEN — GPIOA sleep enable
0x2A0 AHB5LPENR — RCC AHB5 Sleep enable register
  [31] NPULPEN — NPU sleep enable
  [30] NPUCACHELPEN — NPUCACHE sleep enable
  [29] OTG2LPEN — OTG2 sleep enable
  [28] OTGPHY2LPEN — OTGPHY2 sleep enable
  [27] OTGPHY1LPEN — OTGPHY1 sleep enable
  [26] OTG1LPEN — OTG1 sleep enable
  [25] ETH1LPEN — ETH1 sleep enable
  [24] ETH1RXLPEN — ETH1RX sleep enable
  [23] ETH1TXLPEN — ETH1TX sleep enable
  [22] ETH1MACLPEN — ETH1MAC sleep enable
  [20] GPULPEN — GPU sleep enable
  [19] GFXMMULPEN — GFXMMU sleep enable
  [18] MCE4LPEN — MCE4 sleep enable
  [17] XSPI3LPEN — XSPI3 sleep enable
  [16] MCE3LPEN — MCE3 sleep enable
  [15] MCE2LPEN — MCE2 sleep enable
  [14] MCE1LPEN — MCE1 sleep enable
  [13] XSPIMLPEN — XSPIM sleep enable
  [12] XSPI2LPEN — XSPI2 sleep enable
  [8] SDMMC1LPEN — SDMMC1 sleep enable
  [7] SDMMC2LPEN — SDMMC2 sleep enable
  [6] PSSILPEN — PSSI sleep enable
  [5] XSPI1LPEN — XSPI1 sleep enable
  [4] FMCLPEN — FMC sleep enable
  [3] JPEGLPEN — JPEG sleep enable
  [1] DMA2DLPEN — DMA2D sleep enable
  [0] HPDMA1LPEN — HPDMA1 sleep enable
0x2A4 APB1LLPENR — RCC APB1L Sleep enable register
  [31] UART8LPEN — UART8 sleep enable
  [30] UART7LPEN — UART7 sleep enable
  [25] I3C2LPEN — I3C2 sleep enable
  [24] I3C1LPEN — I3C1 sleep enable
  [23] I2C3LPEN — I2C3 sleep enable
  [22] I2C2LPEN — I2C2 sleep enable
  [21] I2C1LPEN — I2C1 sleep enable
  [20] UART5LPEN — UART5 sleep enable
  [19] UART4LPEN — UART4 sleep enable
  [18] USART3LPEN — USART3 sleep enable
  [17] USART2LPEN — USART2 sleep enable
  [16] SPDIFRX1LPEN — SPDIFRX1 sleep enable
  [15] SPI3LPEN — SPI3 sleep enable
  [14] SPI2LPEN — SPI2 sleep enable
  [13] TIM11LPEN — TIM11 sleep enable
  [12] TIM10LPEN — TIM10 sleep enable
  [11] WWDGLPEN — WWDG sleep enable
  [9] LPTIM1LPEN — LPTIM1 sleep enable
  [8] TIM14LPEN — TIM14 sleep enable
  [7] TIM13LPEN — TIM13 sleep enable
  [6] TIM12LPEN — TIM12 sleep enable
  [n-2] TIM{n}LPEN (n=2..7) — TIM{n} sleep enable
0x2A8 APB1HLPENR — RCC APB1H Sleep enable register
  [18] UCPD1LPEN — UCPD1 sleep enable
  [8] FDCANLPEN — FDCAN sleep enable
  [5] MDIOSLPEN — MDIOS sleep enable
0x2AC APB2LPENR — RCC APB2 Sleep enable register
  [22] SAI2LPEN — SAI2 sleep enable
  [21] SAI1LPEN — SAI1 sleep enable
  [20] SPI5LPEN — SPI5 sleep enable
  [19] TIM9LPEN — TIM9 sleep enable
  [18] TIM17LPEN — TIM17 sleep enable
  [17] TIM16LPEN — TIM16 sleep enable
  [16] TIM15LPEN — TIM15 sleep enable
  [15] TIM18LPEN — TIM18 sleep enable
  [13] SPI4LPEN — SPI4 sleep enable
  [12] SPI1LPEN — SPI1 sleep enable
  [7] USART10LPEN — USART10 sleep enable
  [6] UART9LPEN — UART9 sleep enable
  [5] USART6LPEN — USART6 sleep enable
  [4] USART1LPEN — USART1 sleep enable
  [1] TIM8LPEN — TIM8 sleep enable
  [0] TIM1LPEN — TIM1 sleep enable
0x2B0 APB3LPENR — RCC APB3 Sleep enable register
  [2] DFTLPEN — DFT sleep enable
0x2B4 APB4LLPENR — RCC APB4L Sleep enable register
  [31] SERFLPEN — SERF sleep enable
  [23] R2GNPULPEN — R2GNPU sleep enable
  [22] R2GRETLPEN — R2GRET sleep enable
  [17] RTCAPBLPEN — RTCAPB sleep enable
  [16] RTCLPEN — RTC sleep enable
  [15] VREFBUFLPEN — VREFBUF sleep enable
  [n+7] LPTIM{n}LPEN (n=2..5) — LPTIM{n} sleep enable
  [7] I2C4LPEN — I2C4 sleep enable
  [5] SPI6LPEN — SPI6 sleep enable
  [3] LPUART1LPEN — LPUART1 sleep enable
  [2] HDPLPEN — HDP sleep enable
0x2B8 APB4HLPENR reset 0x2 — RCC APB4H Sleep enable register
  [4] BUSPERFMLPEN — BUSPERFM sleep enable
  [2] DTSLPEN — DTS sleep enable
  [1] BSECLPEN — BSEC sleep enable
  [0] SYSCFGLPEN — SYSCFG sleep enable
0x2BC APB5LPENR — RCC APB5 Sleep enable register
  [6] CSILPEN — CSI sleep enable
  [5] VENCLPEN — VENC sleep enable
  [4] GFXTIMLPEN — GFXTIM sleep enable
  [2] DCMIPPLPEN — DCMIPP sleep enable
  [1] LTDCLPEN — LTDC sleep enable
0x44C RDCR reset 0x60000 — RCC APB5 Sleep enable register
  [27:24] EADLY — BOOTROM sleep enable
  [20:16] MRD — BOOTROM sleep enable
0x780 SECCFGR0 — RCC oscillator secure configuration register0
  [4] HSESEC — Defines the secure protection of the HSE oscillator configuration bits.
  [3] HSISEC — Defines the secure protection of the HSI oscillator configuration bits.
  [2] MSISEC — Defines the secure protection of the MSI oscillator configuration bits.
  [1] LSESEC — Defines the secure protection of the LSE oscillator configuration bits.
  [0] LSISEC — Defines the secure protection of the LSI oscillator configuration bits.
0x784 PRIVCFGR0 — RCC oscillator privilege configuration register0
  [4] HSEPV — Defines the privilege protection of the HSE oscillator configuration bits.
  [3] HSIPV — Defines the privilege protection of the HSI oscillator configuration bits.
  [2] MSIPV — Defines the privilege protection of the MSI oscillator configuration bits.
  [1] LSEPV — Defines the privilege protection of the LSE oscillator configuration bits.
  [0] LSIPV — Defines the privilege protection of the LSI oscillator configuration bits.
0x788 LOCKCFGR0 wo — RCC oscillator lock configuration register0
  [4] HSELOCK — Defines the lock protection of the HSE oscillator configuration bits.
  [3] HSILOCK — Defines the lock protection of the HSI oscillator configuration bits.
  [2] MSILOCK — Defines the lock protection of the MSI oscillator configuration bits.
  [1] LSELOCK — Defines the lock protection of the LSE oscillator configuration bits.
  [0] LSILOCK — Defines the lock protection of the LSI oscillator configuration bits.
0x78C PUBCFGR0 — RCC oscillator public configuration register0
  [4] HSEPUB — Defines the public protection of the HSE oscillator configuration bits.
  [3] HSIPUB — Defines the public protection of the HSI oscillator configuration bits.
  [2] MSIPUB — Defines the public protection of the MSI oscillator configuration bits.
  [1] LSEPUB — Defines the public protection of the LSE oscillator configuration bits.
  [0] LSIPUB — Defines the public protection of the LSI oscillator configuration bits.
0x790 SECCFGR1 — RCC PLL secure configuration register1
  [n-1] PLL{n}SEC (n=1..4) — Defines the secure protection of the PLL{n} PLL configuration bits.
0x794 PRIVCFGR1 — RCC PLL privilege configuration register1
  [n-1] PLL{n}PV (n=1..4) — Defines the privilege protection of the PLL{n} PLL configuration bits.
0x798 LOCKCFGR1 wo — RCC PLL lock configuration register1
  [n-1] PLL{n}LOCK (n=1..4) — Defines the lock protection of the PLL{n} PLL configuration bits.
0x79C PUBCFGR1 — RCC PLL public configuration register1
  [n-1] PLL{n}PUB (n=1..4) — Defines the public protection of the PLL{n} PLL configuration bits.
0x7A0 SECCFGR2 — RCC divider secure configuration register2
  [n-1] IC{n}SEC (n=1..20) — Defines the secure protection of the IC{n} divider configuration bits.
0x7A4 PRIVCFGR2 — RCC divider privilege configuration register2
  [n-1] IC{n}PV (n=1..20) — Defines the privilege protection of the IC{n} divider configuration bits.
0x7A8 LOCKCFGR2 wo — RCC divider lock configuration register2
  [n-1] IC{n}LOCK (n=1..20) — Defines the lock protection of the IC{n} divider configuration bits.
0x7AC PUBCFGR2 — RCC divider public configuration register2
  [n-1] IC{n}PUB (n=1..20) — Defines the public protection of the IC{n} divider configuration bits.
0x7B0 SECCFGR3 — RCC system secure configuration register3
  [6] DFTSEC — Defines the secure protection of the DFT system configuration bits.
  [5] RSTSEC — Defines the secure protection of the RST system configuration bits.
  [4] INTSEC — Defines the secure protection of the INT system configuration bits.
  [3] PERSEC — Defines the secure protection of the PER system configuration bits.
  [2] BUSSEC — Defines the secure protection of the BUS system configuration bits.
  [1] SYSSEC — Defines the secure protection of the SYS system configuration bits.
  [0] MODSEC — Defines the secure protection of the MOD system configuration bits.
0x7B4 PRIVCFGR3 — RCC system privilege configuration register3
  [6] DFTPV — Defines the privilege protection of the DFT system configuration bits.
  [5] RSTPV — Defines the privilege protection of the RST system configuration bits.
  [4] INTPV — Defines the privilege protection of the INT system configuration bits.
  [3] PERPV — Defines the privilege protection of the PER system configuration bits.
  [2] BUSPV — Defines the privilege protection of the BUS system configuration bits.
  [1] SYSPV — Defines the privilege protection of the SYS system configuration bits.
  [0] MODPV — Defines the privilege protection of the MOD system configuration bits.
0x7B8 LOCKCFGR3 wo — RCC system lock configuration register3
  [6] DFTLOCK — Defines the lock protection of the DFT system configuration bits.
  [5] RSTLOCK — Defines the lock protection of the RST system configuration bits.
  [4] INTLOCK — Defines the lock protection of the INT system configuration bits.
  [3] PERLOCK — Defines the lock protection of the PER system configuration bits.
  [2] BUSLOCK — Defines the lock protection of the BUS system configuration bits.
  [1] SYSLOCK — Defines the lock protection of the SYS system configuration bits.
  [0] MODLOCK — Defines the lock protection of the MOD system configuration bits.
0x7BC PUBCFGR3 — RCC system public configuration register3
  [6] DFTPUB — Defines the public protection of the DFT system configuration bits.
  [5] RSTPUB — Defines the public protection of the RST system configuration bits.
  [4] INTPUB — Defines the public protection of the INT system configuration bits.
  [3] PERPUB — Defines the public protection of the PER system configuration bits.
  [2] BUSPUB — Defines the public protection of the BUS system configuration bits.
  [1] SYSPUB — Defines the public protection of the SYS system configuration bits.
  [0] MODPUB — Defines the public protection of the MOD system configuration bits.
0x7C0 SECCFGR4 — RCC bus secure configuration register4
  [13] NOCSEC — Defines the secure protection of the NOC bus configuration bits.
  [n+7] APB{n}SEC (n=1..5) — Defines the secure protection of the APB{n} bus configuration bits.
  [n+2] AHB{n}SEC (n=1..5) — Defines the secure protection of the AHB{n} bus configuration bits.
  [2] AHBMSEC — Defines the secure protection of the AHBM bus configuration bits.
  [1] ACLKNCSEC — Defines the secure protection of the ACLKNC bus configuration bits.
  [0] ACLKNSEC — Defines the secure protection of the ACLKN bus configuration bits.
0x7C4 PRIVCFGR4 — RCC bus privilege configuration register4
  [13] NOCPV — Defines the privilege protection of the NOC bus configuration bits.
  [n+7] APB{n}PV (n=1..5) — Defines the privilege protection of the APB{n} bus configuration bits.
  [n+2] AHB{n}PV (n=1..5) — Defines the privilege protection of the AHB{n} bus configuration bits.
  [2] AHBMPV — Defines the privilege protection of the AHBM bus configuration bits.
  [1] ACLKNCPV — Defines the privilege protection of the ACLKNC bus configuration bits.
  [0] ACLKNPV — Defines the privilege protection of the ACLKN bus configuration bits.
0x7C8 LOCKCFGR4 wo — RCC bus lock configuration register4
  [13] NOCLOCK — Defines the lock protection of the NOC bus configuration bits.
  [n+7] APB{n}LOCK (n=1..5) — Defines the lock protection of the APB{n} bus configuration bits.
  [n+2] AHB{n}LOCK (n=1..5) — Defines the lock protection of the AHB{n} bus configuration bits.
  [2] AHBMLOCK — Defines the lock protection of the AHBM bus configuration bits.
  [1] ACLKNCLOCK — Defines the lock protection of the ACLKNC bus configuration bits.
  [0] ACLKNLOCK — Defines the lock protection of the ACLKN bus configuration bits.
0x7CC PUBCFGR4 — RCC bus public configuration register4
  [13] NOCPUB — Defines the public protection of the NOC bus configuration bits.
  [n+7] APB{n}PUB (n=1..5) — Defines the public protection of the APB{n} bus configuration bits.
  [n+2] AHB{n}PUB (n=1..5) — Defines the public protection of the AHB{n} bus configuration bits.
  [2] AHBMPUB — Defines the public protection of the AHBM bus configuration bits.
  [1] ACLKNCPUB — Defines the public protection of the ACLKNC bus configuration bits.
  [0] ACLKNPUB — Defines the public protection of the ACLKN bus configuration bits.
0x7D0 PUBCFGR5 — RCC bus public configuration register4
  [11] VENCRAMPUB — Defines the public protection of the VENCRAM bus configuration bits.
  [10] NPUCACHERAMPUB — Defines the public protection of the NPUCACHERAM bus configuration bits.
  [9] FLEXRAMPUB — Defines the public protection of the FLEXRAM bus configuration bits.
  [8] AXISRAM2PUB — Defines the public protection of the AXISRAM2 bus configuration bits.
  [7] AXISRAM1PUB — Defines the public protection of the AXISRAM1 bus configuration bits.
  [6] BKPSRAMPUB — Defines the public protection of the BKPSRAM bus configuration bits.
  [5] AHBSRAM2PUB — Defines the public protection of the AHBSRAM2 bus configuration bits.
  [4] AHBSRAM1PUB — Defines the public protection of the AHBSRAM1 bus configuration bits.
  [n-3] AXISRAM{n}PUB (n=3..6) — Defines the public protection of the AXISRAM{n} bus configuration bits.
0x800 CSR wo — RCC control set register
  [n+7] PLL{n}ONS (n=1..4) — PLL{n} oscillator enable in Run/Sleep mode.
  [4] HSEONS — HSE oscillator enable in Run/Sleep mode.
  [3] HSIONS — HSI oscillator enable in Run/Sleep mode.
  [2] MSIONS — MSI oscillator enable in Run/Sleep mode.
  [1] LSEONS — LSE oscillator enable in Run/Sleep mode.
  [0] LSIONS — LSI oscillator enable in Run/Sleep mode.
0x808 STOPCSR wo — RCC Stop configuration register
  [1] HSISTOPENS, [0] MSISTOPENS
0xA04 BUSRSTSR wo — RCC bus reset set register
  [13] NOCRSTS — NOC reset
  [n+7] APB{n}RSTS (n=1..5) — APB{n} reset
  [n+2] AHB{n}RSTS (n=1..5) — AHB{n} reset
  [2] AHBMRSTS — AHBM reset
  [0] ACLKNRSTS — ACLKN reset
0xA08 MISCRSTSR wo — RCC miscellaneous reset register
  [8] SDMMC2DLLRSTS — SDMMC2DLL reset
  [7] SDMMC1DLLRSTS — SDMMC1DLL reset
  [5] XSPIPHY2RSTS — XSPIPHY2 reset
  [4] XSPIPHY1RSTS — XSPIPHY1 reset
  [0] DBGRSTS — DBG reset
0xA0C MEMRSTSR wo — RCC memory reset register
  [12] BOOTROMRSTS — BOOTROM reset
  [11] VENCRAMRSTS — VENCRAM reset
  [10] NPUCACHERAMRSTS — NPUCACHERAM reset
  [9] FLEXRAMRSTS — FLEXRAM reset
  [8] AXISRAM2RSTS — AXISRAM2 reset
  [7] AXISRAM1RSTS — AXISRAM1 reset
  [5] AHBSRAM2RSTS — AHBSRAM2 reset
  [4] AHBSRAM1RSTS — AHBSRAM1 reset
  [n-3] AXISRAM{n}RSTS (n=3..6) — AXISRAM{n} reset
0xA10 AHB1RSTSR wo — RCC AHB1 reset register
  [5] ADC12RSTS — ADC12 reset
  [4] GPDMA1RSTS — GPDMA1 reset
0xA14 AHB2RSTSR wo — RCC AHB2 reset register
  [17] ADF1RSTS — ADF1 reset
  [16] MDF1RSTS — MDF1 reset
  [12] RAMCFGRSTS — RAMCFG reset
0xA18 AHB3RSTSR wo — RCC AHB3 reset register
  [10] IACRSTS — IAC reset
  [8] PKARSTS — PKA reset
  [4] SAESRSTS — SAES reset
  [2] CRYPRSTS — CRYP reset
  [1] HASHRSTS — HASH reset
  [0] RNGRSTS — RNG reset
0xA1C AHB4RSTSR wo — RCC AHB4 reset register
  [19] CRCRSTS — CRC reset
  [18] PWRRSTS — PWR reset
  [16] GPIOQRSTS — GPIOQ reset
  [15] GPIOPRSTS — GPIOP reset
  [14] GPIOORSTS — GPIOO reset
  [13] GPIONRSTS — GPION reset
  [7] GPIOHRSTS — GPIOH reset
  [6] GPIOGRSTS — GPIOG reset
  [5] GPIOFRSTS — GPIOF reset
  [4] GPIOERSTS — GPIOE reset
  [3] GPIODRSTS — GPIOD reset
  [2] GPIOCRSTS — GPIOC reset
  [1] GPIOBRSTS — GPIOB reset
  [0] GPIOARSTS — GPIOA reset
0xA20 AHB5RSTSR wo — RCC AHB5 reset register
  [31] NPURSTS — NPU reset
  [30] NPUCACHERSTS — NPUCACHE reset
  [29] OTG2RSTS — OTG2 reset
  [28] OTGPHY2RSTS — OTGPHY2 reset
  [27] OTGPHY1RSTS — OTGPHY1 reset
  [26] OTG1RSTS — OTG1 reset
  [25] ETH1RSTS — ETH1 reset
  [24] SYSCFGOTGHSPHY2RSTS — SYSCFGOTGHSPHY2 reset
  [23] SYSCFGOTGHSPHY1RSTS — SYSCFGOTGHSPHY1 reset
  [20] GPURSTS — GPU reset
  [19] GFXMMURSTS — GFXMMU reset
  [18] MCE4RSTS — MCE4 reset
  [17] XSPI3RSTS — XSPI3 reset
  [13] XSPIMRSTS — XSPIM reset
  [12] XSPI2RSTS — XSPI2 reset
  [8] SDMMC1RSTS — SDMMC1 reset
  [7] SDMMC2RSTS — SDMMC2 reset
  [6] PSSIRSTS — PSSI reset
  [5] XSPI1RSTS — XSPI1 reset
  [4] FMCRSTS — FMC reset
  [3] JPEGRSTS — JPEG reset
  [1] DMA2DRSTS — DMA2D reset
  [0] HPDMA1RSTS — HPDMA1 reset
0xA24 APB1LRSTSR wo — RCC APB1L reset register
  [31] UART8RSTS — UART8 reset
  [30] UART7RSTS — UART7 reset
  [25] I3C2RSTS — I3C2 reset
  [24] I3C1RSTS — I3C1 reset
  [23] I2C3RSTS — I2C3 reset
  [22] I2C2RSTS — I2C2 reset
  [21] I2C1RSTS — I2C1 reset
  [20] UART5RSTS — UART5 reset
  [19] UART4RSTS — UART4 reset
  [18] USART3RSTS — USART3 reset
  [17] USART2RSTS — USART2 reset
  [16] SPDIFRX1RSTS — SPDIFRX1 reset
  [15] SPI3RSTS — SPI3 reset
  [14] SPI2RSTS — SPI2 reset
  [13] TIM11RSTS — TIM11 reset
  [12] TIM10RSTS — TIM10 reset
  [11] WWDGRSTS — WWDG reset
  [9] LPTIM1RSTS — LPTIM1 reset
  [8] TIM14RSTS — TIM14 reset
  [7] TIM13RSTS — TIM13 reset
  [6] TIM12RSTS — TIM12 reset
  [n-2] TIM{n}RSTS (n=2..7) — TIM{n} reset
